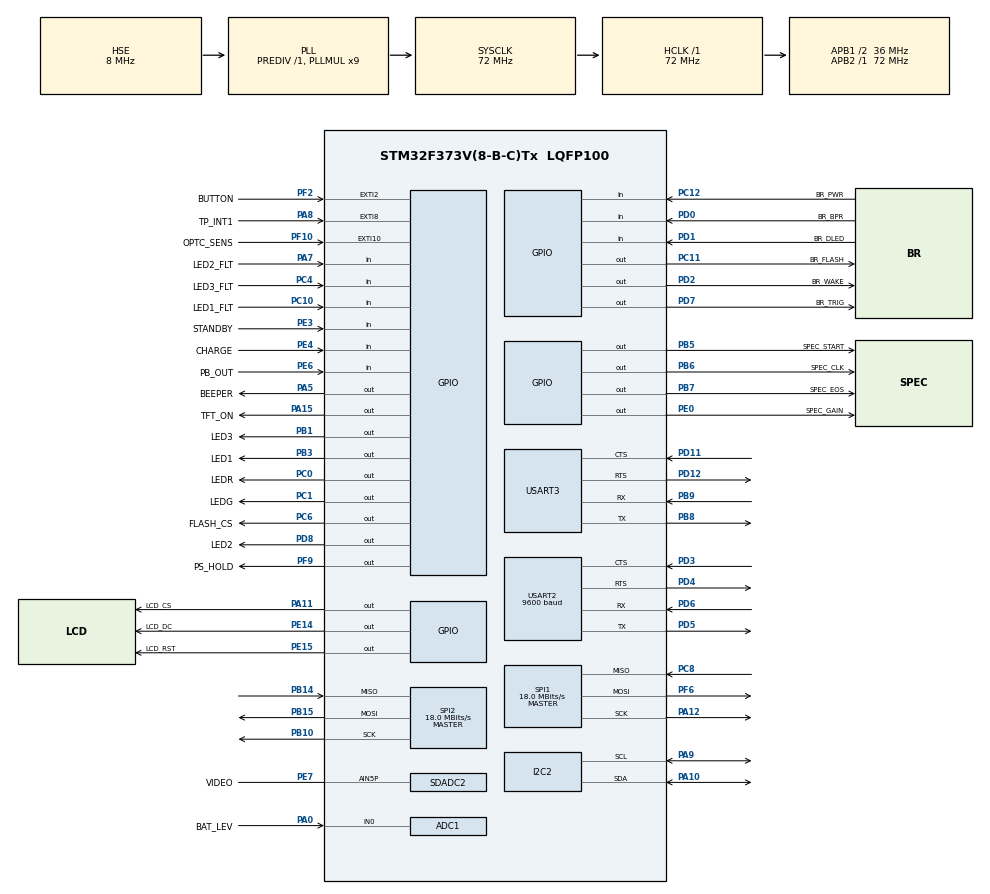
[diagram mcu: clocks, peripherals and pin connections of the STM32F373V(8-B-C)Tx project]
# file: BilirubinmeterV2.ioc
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ADC1.Channel-0\#ChannelRegularConversion=ADC_CHANNEL_0
ADC1.ContinuousConvMode=ENABLE
ADC1.NbrOfConversion=1
ADC1.NbrOfConversionFlag=1
ADC1.Rank-0\#ChannelRegularConversion=1
ADC1.SamplingTime-0\#ChannelRegularConversion=ADC_SAMPLETIME_1CYCLE_5
ADC1.master=1
Dma.ADC1.3.Direction=DMA_PERIPH_TO_MEMORY
Dma.ADC1.3.Instance=DMA1_Channel1
Dma.ADC1.3.MemDataAlignment=DMA_MDATAALIGN_HALFWORD
Dma.ADC1.3.MemInc=DMA_MINC_ENABLE
Dma.ADC1.3.Mode=DMA_CIRCULAR
Dma.ADC1.3.PeriphDataAlignment=DMA_PDATAALIGN_HALFWORD
Dma.ADC1.3.PeriphInc=DMA_PINC_DISABLE
Dma.ADC1.3.Priority=DMA_PRIORITY_LOW
Dma.Request0=USART2_RX
Dma.Request1=USART3_RX
Dma.Request2=USART3_TX
Dma.Request3=ADC1
Dma.USART2_RX.0.Direction=DMA_PERIPH_TO_MEMORY
Dma.USART2_RX.0.Instance=DMA1_Channel6
Dma.USART2_RX.0.MemDataAlignment=DMA_MDATAALIGN_BYTE
Dma.USART2_RX.0.MemInc=DMA_MINC_ENABLE
Dma.USART2_RX.0.Mode=DMA_CIRCULAR
Dma.USART2_RX.0.PeriphDataAlignment=DMA_PDATAALIGN_BYTE
Dma.USART2_RX.0.PeriphInc=DMA_PINC_DISABLE
Dma.USART2_RX.0.Priority=DMA_PRIORITY_LOW
Dma.USART3_RX.1.Direction=DMA_PERIPH_TO_MEMORY
Dma.USART3_RX.1.Instance=DMA1_Channel3
Dma.USART3_RX.1.MemDataAlignment=DMA_MDATAALIGN_BYTE
Dma.USART3_RX.1.MemInc=DMA_MINC_ENABLE
Dma.USART3_RX.1.Mode=DMA_CIRCULAR
Dma.USART3_RX.1.PeriphDataAlignment=DMA_PDATAALIGN_BYTE
Dma.USART3_RX.1.PeriphInc=DMA_PINC_DISABLE
Dma.USART3_RX.1.Priority=DMA_PRIORITY_LOW
Dma.USART3_TX.2.Direction=DMA_MEMORY_TO_PERIPH
Dma.USART3_TX.2.Instance=DMA1_Channel2
Dma.USART3_TX.2.MemDataAlignment=DMA_MDATAALIGN_BYTE
Dma.USART3_TX.2.MemInc=DMA_MINC_ENABLE
Dma.USART3_TX.2.Mode=DMA_CIRCULAR
Dma.USART3_TX.2.PeriphDataAlignment=DMA_PDATAALIGN_BYTE
Dma.USART3_TX.2.PeriphInc=DMA_PINC_DISABLE
Dma.USART3_TX.2.Priority=DMA_PRIORITY_LOW
Mcu.Family=STM32F3
Mcu.Name=STM32F373V(8-B-C)Tx
Mcu.Package=LQFP100
NVIC.DMA1_Channel1_IRQn=true\:0\:0\:false\:false\:true\:false\:true
NVIC.DMA1_Channel2_IRQn=true\:0\:0\:false\:false\:true\:false\:true
NVIC.DMA1_Channel3_IRQn=true\:0\:0\:false\:false\:true\:false\:true
NVIC.DMA1_Channel6_IRQn=true\:0\:0\:false\:false\:true\:false\:true
NVIC.EXTI15_10_IRQn=true\:0\:0\:false\:false\:true\:true\:true
NVIC.EXTI2_TSC_IRQn=true\:0\:0\:false\:false\:true\:true\:true
NVIC.EXTI9_5_IRQn=true\:0\:0\:false\:false\:true\:true\:true
NVIC.PriorityGroup=NVIC_PRIORITYGROUP_4
NVIC.SDADC2_IRQn=true\:0\:0\:false\:false\:true\:true\:true
NVIC.USART2_IRQn=true\:0\:0\:false\:false\:true\:true\:true
NVIC.USART3_IRQn=true\:0\:0\:false\:false\:true\:true\:true
PA0.GPIO_Label=BAT_LEV
PA0.Mode=IN0
PA0.Signal=ADC1_IN0
PA10.Mode=I2C
PA10.Signal=I2C2_SDA
PA11.GPIO_Label=LCD_CS
PA11.Signal=GPIO_Output
PA12.Mode=Full_Duplex_Master
PA12.Signal=SPI1_SCK
PA15.GPIO_Label=TFT_ON
PA15.Signal=GPIO_Output
PA5.GPIO_Label=BEEPER
PA5.Signal=GPIO_Output
PA7.GPIO_Label=LED2_FLT
PA7.Signal=GPIO_Input
PA8.GPIO_Label=TP_INT1
PA8.Signal=GPXTI8
PA9.Mode=I2C
PA9.Signal=I2C2_SCL
PB1.GPIO_Label=LED3
PB1.Signal=GPIO_Output
PB10.Mode=Full_Duplex_Master
PB10.Signal=SPI2_SCK
PB14.Mode=Full_Duplex_Master
PB14.Signal=SPI2_MISO
PB15.Mode=Full_Duplex_Master
PB15.Signal=SPI2_MOSI
PB3.GPIO_Label=LED1
PB3.GPIO_Speed=GPIO_SPEED_FREQ_HIGH
PB3.PinState=GPIO_PIN_RESET
PB3.Signal=GPIO_Output
PB5.GPIO_Label=SPEC_START
PB5.GPIO_Speed=GPIO_SPEED_FREQ_HIGH
PB5.Signal=GPIO_Output
PB6.GPIO_FM6=SYSCFG_CFGR1_I2C_PB6_FMP
PB6.GPIO_Label=SPEC_CLK
PB6.GPIO_Speed=GPIO_SPEED_FREQ_HIGH
PB6.Signal=GPIO_Output
PB7.GPIO_FM7=SYSCFG_CFGR1_I2C_PB7_FMP
PB7.GPIO_Label=SPEC_EOS
PB7.GPIO_Speed=GPIO_SPEED_FREQ_HIGH
PB7.Signal=GPIO_Output
PB8.Mode=Asynchronous
PB8.Signal=USART3_TX
PB9.Mode=Asynchronous
PB9.Signal=USART3_RX
PC0.GPIO_Label=LEDR
PC0.Signal=GPIO_Output
PC1.GPIO_Label=LEDG
PC1.Signal=GPIO_Output
PC10.GPIO_Label=LED1_FLT
PC10.Signal=GPIO_Input
PC11.GPIO_Label=BR_FLASH
PC11.GPIO_ModeDefaultOutputPP=GPIO_MODE_OUTPUT_PP
PC11.GPIO_PuPd=GPIO_NOPULL
PC11.GPIO_Speed=GPIO_SPEED_FREQ_LOW
PC11.PinState=GPIO_PIN_RESET
PC11.Signal=GPIO_Output
PC12.GPIO_Label=BR_PWR
PC12.GPIO_Mode=GPIO_MODE_INPUT
PC12.GPIO_PuPd=GPIO_NOPULL
PC12.Signal=GPIO_Input
PC14-OSC32_IN.Mode=LSE-External-Oscillator
PC14-OSC32_IN.Signal=RCC_OSC32_IN
PC15-OSC32_OUT.Mode=LSE-External-Oscillator
PC15-OSC32_OUT.Signal=RCC_OSC32_OUT
PC4.GPIO_Label=LED3_FLT
PC4.Signal=GPIO_Input
PC6.GPIO_Label=FLASH_CS
PC6.Signal=GPIO_Output
PC8.Mode=Full_Duplex_Master
PC8.Signal=SPI1_MISO
PD0.GPIO_Label=BR_BPR
PD0.GPIO_Mode=GPIO_MODE_INPUT
PD0.GPIO_PuPd=GPIO_NOPULL
PD0.Signal=GPIO_Input
PD1.GPIO_Label=BR_DLED
PD1.GPIO_Mode=GPIO_MODE_INPUT
PD1.GPIO_PuPd=GPIO_NOPULL
PD1.Signal=GPIO_Input
PD11.Mode=CTS_RTS
PD11.Signal=USART3_CTS
PD12.Mode=CTS_RTS
PD12.Signal=USART3_RTS
PD2.GPIO_Label=BR_WAKE
PD2.GPIO_ModeDefaultOutputPP=GPIO_MODE_OUTPUT_PP
PD2.GPIO_PuPd=GPIO_NOPULL
PD2.GPIO_Speed=GPIO_SPEED_FREQ_LOW
PD2.PinState=GPIO_PIN_RESET
PD2.Signal=GPIO_Output
PD3.Mode=CTS_RTS
PD3.Signal=USART2_CTS
PD4.Mode=CTS_RTS
PD4.Signal=USART2_RTS
PD5.Mode=Asynchronous
PD5.Signal=USART2_TX
PD6.Mode=Asynchronous
PD6.Signal=USART2_RX
PD7.GPIO_Label=BR_TRIG
PD7.GPIO_ModeDefaultOutputPP=GPIO_MODE_OUTPUT_PP
PD7.GPIO_PuPd=GPIO_NOPULL
PD7.GPIO_Speed=GPIO_SPEED_FREQ_LOW
PD7.PinState=GPIO_PIN_RESET
PD7.Signal=GPIO_Output
PD8.GPIO_Label=LED2
PD8.Signal=GPIO_Output
PE0.GPIO_Label=SPEC_GAIN
PE0.GPIO_Speed=GPIO_SPEED_FREQ_LOW
PE0.Signal=GPIO_Output
PE14.GPIO_Label=LCD_DC
PE14.Signal=GPIO_Output
PE15.GPIO_Label=LCD_RST
PE15.Signal=GPIO_Output
PE3.GPIO_Label=STANDBY
PE3.Signal=GPIO_Input
PE4.GPIO_Label=CHARGE
PE4.Signal=GPIO_Input
PE6.GPIO_Label=PB_OUT
PE6.Signal=GPIO_Input
PE7.GPIO_Label=VIDEO
PE7.GPIO_Mode=GPIO_MODE_ANALOG
PE7.GPIO_PuPd=GPIO_NOPULL
PE7.Mode=IN5-Single-Ended zero reference
PE7.Signal=SDADC2_AIN5P
PF0-OSC_IN.Mode=HSE-External-Oscillator
PF0-OSC_IN.Signal=RCC_OSC_IN
PF1-OSC_OUT.Mode=HSE-External-Oscillator
PF1-OSC_OUT.Signal=RCC_OSC_OUT
PF10.GPIO_Label=OPTC_SENS
PF10.Signal=GPXTI10
PF2.GPIO_Label=BUTTON
PF2.Signal=GPXTI2
PF6.Mode=Full_Duplex_Master
PF6.Signal=SPI1_MOSI
PF9.GPIO_Label=PS_HOLD
PF9.Signal=GPIO_Output
ProjectManager.HeapSize=0x200
ProjectManager.StackSize=0x400
ProjectManager.TargetToolchain=MDK-ARM V5
RCC.AHBFreq_Value=72000000
RCC.APB1CLKDivider=RCC_HCLK_DIV2
RCC.APB1Freq_Value=36000000
RCC.APB1TimFreq_Value=72000000
RCC.APB2Freq_Value=72000000
RCC.APB2TimFreq_Value=72000000
RCC.CortexFreq_Value=72000000
RCC.HCLKFreq_Value=72000000
RCC.HSE_VALUE=8000000
RCC.HSI_VALUE=8000000
RCC.PLLMUL=RCC_PLL_MUL9
RCC.PLLSourceVirtual=RCC_PLLSOURCE_HSE
RCC.RTCClockSelection=RCC_RTCCLKSOURCE_LSE
RCC.SDADCPresc=RCC_SDADCSYSCLK_DIV12
RCC.SYSCLKFreq_VALUE=72000000
RCC.SYSCLKSource=RCC_SYSCLKSOURCE_PLLCLK
RCC.USBFreq_Value=72000000
RTC.Format=RTC_FORMAT_BIN
RTC.Hours=14
RTC.Minutes=20
RTC.Month=RTC_MONTH_APRIL
RTC.WeekDay=RTC_WEEKDAY_FRIDAY
RTC.Year=20
SDADC2.EnableInjectedConversion=ENABLE
SDADC2.InjNumberOfConversion=1
SDADC2.InjectedChannel-1\#ChannelInjectedConversion=SDADC_CHANNEL_5
SDADC2.InjectedChannelsSelection=SDADC_CHANNEL_5
SDADC2.InjectedConfIndex-1\#ChannelInjectedConversion=SDADC_CONF_INDEX_0
SDADC2.InjectedContinuousMode=SDADC_CONTINUOUS_CONV_ON
SDADC2.InjectedRank-1\#ChannelInjectedConversion=1
SDADC2.InputMode0=SDADC_INPUT_MODE_SE_ZERO_REFERENCE
SDADC2.NbrOfConversionFlag=1
SPI1.BaudRatePrescaler=SPI_BAUDRATEPRESCALER_4
SPI1.CalculateBaudRate=18.0 MBits/s
SPI1.DataSize=SPI_DATASIZE_8BIT
SPI1.Direction=SPI_DIRECTION_2LINES
SPI1.Mode=SPI_MODE_MASTER
SPI1.VirtualType=VM_MASTER
SPI2.CalculateBaudRate=18.0 MBits/s
SPI2.DataSize=SPI_DATASIZE_8BIT
SPI2.Direction=SPI_DIRECTION_2LINES
SPI2.Mode=SPI_MODE_MASTER
SPI2.VirtualType=VM_MASTER
TIM6.Period=10000
TIM6.Prescaler=14400
USART2.BaudRate=9600
USART2.VirtualMode-Asynchronous=VM_ASYNC
USART3.VirtualMode-Asynchronous=VM_ASYNC
VP_RTC_VS_RTC_Activate.Mode=RTC_Enabled
VP_RTC_VS_RTC_Calendar.Mode=RTC_Calendar
VP_SDADC2_CONF0.Mode=ConfigZero
VP_TIM6_VS_ClockSourceINT.Mode=Enable_Timer
board=custom

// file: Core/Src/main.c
/* USER CODE BEGIN Header */
/**
  ******************************************************************************
  * @file           : main.c
  * @brief          : Main program body
  ******************************************************************************
  * @attention
  *
  * <h2><center>&copy; Copyright (c) 2020 STMicroelectronics.
  * All rights reserved.</center></h2>
  *
  * This software component is licensed by ST under BSD 3-Clause license,
  * the "License"; You may not use this file except in compliance with the
  * License. You may obtain a copy of the License at:
  *                        opensource.org/licenses/BSD-3-Clause
  *
  ******************************************************************************
  */
/* USER CODE END Header */

#include "main.h"
#include "adc.h"
#include "dma.h"
#include "i2c.h"
#include "rtc.h"
#include "sdadc.h"
#include "spi.h"
#include "tim.h"
#include "usart.h"
#include "gpio.h"

/* USER CODE BEGIN PV */
bool B_Status;
/* USER CODE END PV */

void SystemClock_Config(void);

int main(void)
{

  /* MCU Configuration--------------------------------------------------------*/

  /* Reset of all peripherals, Initializes the Flash interface and the Systick. */
  HAL_Init();

  /* Configure the system clock */
  SystemClock_Config();

  /* USER CODE BEGIN SysInit */
	HAL_Delay(200);
  /* USER CODE END SysInit */

  /* Initialize all configured peripherals */
  MX_GPIO_Init();
  MX_DMA_Init();
  MX_ADC1_Init();
  MX_I2C2_Init();
  MX_SDADC2_Init();
  MX_SPI1_Init();
  MX_SPI2_Init();
  MX_USART2_UART_Init();
  MX_USART3_UART_Init();
  MX_RTC_Init();
  MX_TIM6_Init();
  /* USER CODE BEGIN 2 */

	do{

		B_Status = HAL_GPIO_ReadPin(BUTTON_GPIO_Port,BUTTON_Pin); // buton sorunu için geçici çözüm, basilincaya kadar ekran açilmiyor (109-115 arasi)

		}
	while(B_Status != 0);

	POWER_ON
	LED_OFF
	HAL_UART_Receive_DMA(&huart2,rx_buff,13);
	SysInit();

  /* USER CODE END 2 */

  /* Infinite loop */
  while (1)
  {
  }

}

void SystemClock_Config(void)
{
  RCC_OscInitTypeDef RCC_OscInitStruct = {0};
  RCC_ClkInitTypeDef RCC_ClkInitStruct = {0};
  RCC_PeriphCLKInitTypeDef PeriphClkInit = {0};

  /** Configure LSE Drive Capability
  */
  HAL_PWR_EnableBkUpAccess();
  __HAL_RCC_LSEDRIVE_CONFIG(RCC_LSEDRIVE_LOW);
  /** Initializes the CPU, AHB and APB busses clocks
  */
  RCC_OscInitStruct.OscillatorType = RCC_OSCILLATORTYPE_HSI|RCC_OSCILLATORTYPE_HSE
                              |RCC_OSCILLATORTYPE_LSE;
  RCC_OscInitStruct.HSEState = RCC_HSE_ON;
  RCC_OscInitStruct.HSEPredivValue = RCC_HSE_PREDIV_DIV1;
  RCC_OscInitStruct.LSEState = RCC_LSE_ON;
  RCC_OscInitStruct.HSIState = RCC_HSI_ON;
  RCC_OscInitStruct.HSICalibrationValue = RCC_HSICALIBRATION_DEFAULT;
  RCC_OscInitStruct.PLL.PLLState = RCC_PLL_ON;
  RCC_OscInitStruct.PLL.PLLSource = RCC_PLLSOURCE_HSE;
  RCC_OscInitStruct.PLL.PLLMUL = RCC_PLL_MUL9;
  if (HAL_RCC_OscConfig(&RCC_OscInitStruct) != HAL_OK)
  {
    Error_Handler();
  }
  /** Initializes the CPU, AHB and APB busses clocks
  */
  RCC_ClkInitStruct.ClockType = RCC_CLOCKTYPE_HCLK|RCC_CLOCKTYPE_SYSCLK
                              |RCC_CLOCKTYPE_PCLK1|RCC_CLOCKTYPE_PCLK2;
  RCC_ClkInitStruct.SYSCLKSource = RCC_SYSCLKSOURCE_PLLCLK;
  RCC_ClkInitStruct.AHBCLKDivider = RCC_SYSCLK_DIV1;
  RCC_ClkInitStruct.APB1CLKDivider = RCC_HCLK_DIV2;
  RCC_ClkInitStruct.APB2CLKDivider = RCC_HCLK_DIV1;

  if (HAL_RCC_ClockConfig(&RCC_ClkInitStruct, FLASH_LATENCY_2) != HAL_OK)
  {
    Error_Handler();
  }
  PeriphClkInit.PeriphClockSelection = RCC_PERIPHCLK_USART2|RCC_PERIPHCLK_USART3
                              |RCC_PERIPHCLK_I2C2|RCC_PERIPHCLK_RTC
                              |RCC_PERIPHCLK_ADC1|RCC_PERIPHCLK_SDADC;
  PeriphClkInit.Usart2ClockSelection = RCC_USART2CLKSOURCE_PCLK1;
  PeriphClkInit.Usart3ClockSelection = RCC_USART3CLKSOURCE_PCLK1;
  PeriphClkInit.I2c2ClockSelection = RCC_I2C2CLKSOURCE_HSI;
  PeriphClkInit.RTCClockSelection = RCC_RTCCLKSOURCE_LSE;
  PeriphClkInit.SdadcClockSelection = RCC_SDADCSYSCLK_DIV12;
  PeriphClkInit.Adc1ClockSelection = RCC_ADC1PCLK2_DIV2;

  if (HAL_RCCEx_PeriphCLKConfig(&PeriphClkInit) != HAL_OK)
  {
    Error_Handler();
  }
  HAL_PWREx_EnableSDADC(PWR_SDADC_ANALOG2);
}

void Error_Handler(void)
{
}

/************************ (C) COPYRIGHT STMicroelectronics *****END OF FILE****/
